# AS32x601 register map
File version: 1.0
CPU: RISC-V, little endian
Registers are 32-bit, read-write, reset 0x0 unless marked. A register's access mark holds for its fields unless they carry their own. Offsets are from the block's base; [hi:lo] are bit positions; {n}, {i} and the like mark numbered series.

## IWDG — Independent Watchdog Timer
Base 0x30104000
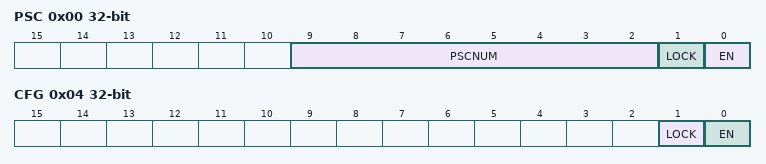
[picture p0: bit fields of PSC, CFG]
0x00 PSC — Prescaler register
  [9:2] PSCNUM — Independent watchdog prescaler number
  [1] LOCK — Independent watchdog prescaler lock
  [0] EN — Enable Independent watchdog prescaler
0x04 CFG — Configuration register
  [1] LOCK — Independent watchdog configuration lock
  [0] EN — Enable Independent watchdog configuration
0x08 DIV — Divider register
  [15:0] DIVNUM — Independent watchdog divider number
0x0C TO — Timeout period register
  [15:0] BVAL — Independent watchdog configure timeout period
0x10 CNT ro — Counter register
  [15:0] CNTNUM — Independent watchdog counter number
0x14 CLR wo — Clear/Refresh register
  [31:0] KEY — Independent watchdog refreshes the key

## WWDG0 — Window Watchdog 0
Base 0x5000D000
Same registers: WWDG1 0x5100C000
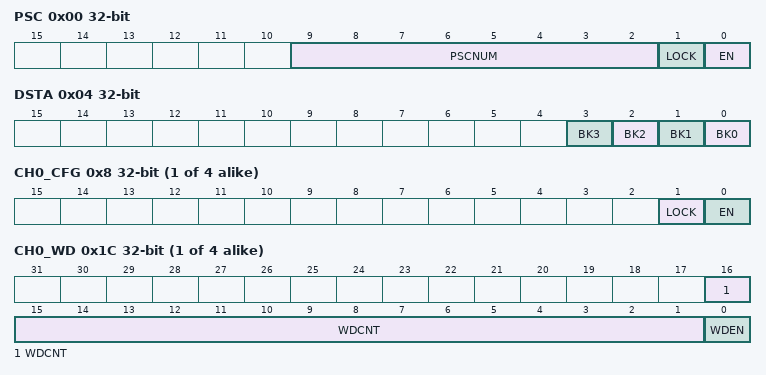
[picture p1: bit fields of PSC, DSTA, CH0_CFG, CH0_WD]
0x00 PSC — WWDG Prescaler register
  [9:2] PSCNUM — Independent watchdog prescaler number
  [1] LOCK — Independent watchdog prescaler lock
  [0] EN — Enable Independent watchdog prescaler
0x04 DSTA ro — WWDG Device Status register
  [n] BK{n} (n=0..3) — The WWDG Channel{n} Bark flag
{0x8+0x18*i} CH{i}_CFG (i=0..3) — WWDG Channel{i} Configuration register
  [1] LOCK — Independent watchdog configuration lock
  [0] EN — Enable Independent watchdog configuration
{0xC+0x18*i} CH{i}_DIV (i=0..3) — WWDG Channel{i} Divider register
  [15:0] DIVNUM — Independent watchdog divider number
{0x10+0x18*i} CH{i}_TO (i=0..3) — WWDG Channel{i} Timeout register
  [15:0] BVAL — Independent watchdog configure timeout period
{0x14+0x18*i} CH{i}_CNT (i=0..3) — WWDG Channel{i} Counter register
  [15:0] CNTNUM — Independent watchdog counter number
{0x18+0x18*i} CH{i}_CLR wo (i=0..3) — WWDG Channel{i} Clear register
  [31:0] KEY — Independent watchdog refreshes the key
{0x1C+0x18*i} CH{i}_WD (i=0..3) — WWDG Channel{i} Window register
  [16:1] WDCNT — WWDG Window Counter Value
  [0] WDEN — Enable WWDG Window Counter

## CRC — Cyclic Redundancy Check Calculation Unit
Base 0x5100D000
0x00 DR — CRC data register
  [31:0] DATA — CRC calculated result bit[31:0]
0x04 IDR — CRC independent data register
  [7:0] IDATA — Universal 8-bit data register bit[7:0]
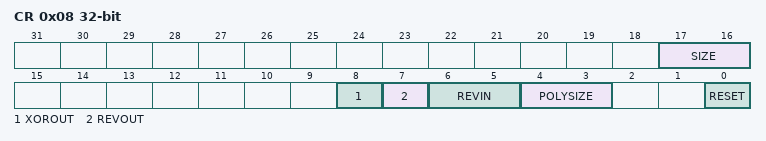
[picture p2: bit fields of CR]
0x08 CR — CRC control register
  [17:16] SIZE — Calculate the size of the data[1:0]
  [8] XOROUT — Output data XOR
  [7] REVOUT — Reverse output data
  [6:5] REVIN — Reverse input data[1:0]
  [4:3] POLYSIZE — Polynomial size[1:0]
  [0] RESET — Reset CRC
0x0C INIT reset 0xFFFFFFFF — CRC initial vector register
  [31:0] INIT — Initial vector register[31:0]
0x10 POLY wo — CRC generates polynomial registers
  [31:0] POLY — Generating polynomial register[31:0]
0x14 XOR wo — CRC XOR polynomial register
  [31:0] XOR — XOR register[31:0]

## CMU0 — Clock Monitoring Unit 0
Base 0x30003000
Same registers: CMU1 0x30003400, CMU2 0x30003800, CMU3 0x30003C00
0x00 CR — CMU Control register
  [2:0] MODE — MODE[2:0] bits (Clock monitoring enabled)
0x04 CCR — Counter configuration register
  [23:0] WINLEN — WINLEN[23:0] bits (Reference Count Window Length)
0x08 HTCR — High threshold configuration register
  [23:0] HFREF — HFREF[23:0] bits (High frequency reference threshold)
0x0C LTCR — Low threshold configuration register
  [23:0] LFREF — LFREF[23:0] bits (Low frequency reference threshold)
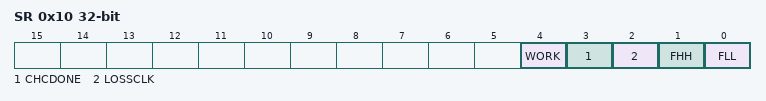
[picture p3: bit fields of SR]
0x10 SR ro — Status register
  [4] WORK — Working condition
  [3] CHCDONE — Status Detection
  [2] LOSSCLK — Clock loss status
  [1] FHH — State where the frequency is greater than the high-frequency reference threshold
  [0] FLL — Frequency below the low frequency reference threshold state

## GPIOH — General-purpose I/Os
Base 0x30102000
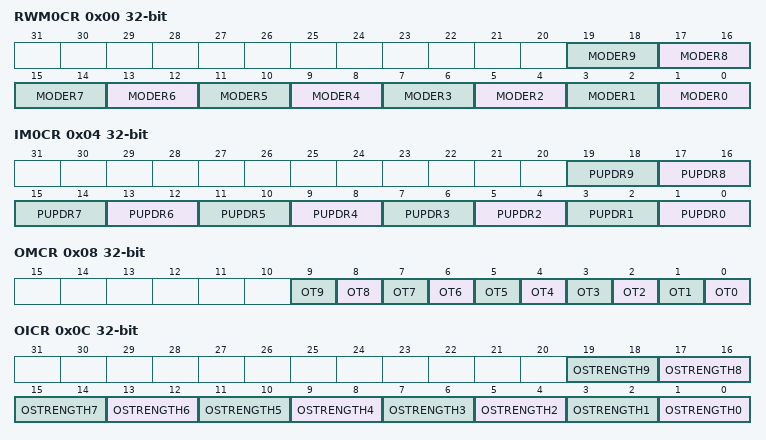
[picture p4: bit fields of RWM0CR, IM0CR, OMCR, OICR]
0x00 RWM0CR — Read/write mode control register 0
  [2n+1:2n] MODER{n} (n=0..9) — Control the read and write mode of Control {n}
0x04 IM0CR — Input mode control register 0
  [2n+1:2n] PUPDR{n} (n=0..9) — Channel {n} input mode control
0x08 OMCR — Output mode control register
  [n] OT{n} (n=0..9) — Channel {n} output mode control
0x0C OICR — Output intensity control register 0
  [2n+1:2n] OSTRENGTH{n} (n=0..9) — Channel {n} output strength control
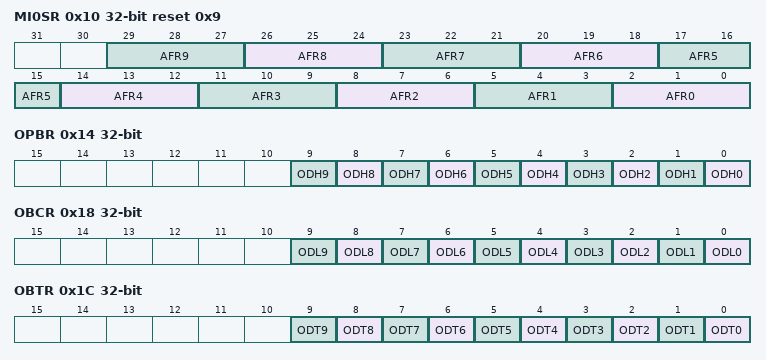
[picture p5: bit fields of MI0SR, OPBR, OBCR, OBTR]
0x10 MI0SR reset 0x9 — Multiplex interface select register 0
  [3n+2:3n] AFR{n} (n=0..9) — Channel {n} multiplexing interface selection
0x14 OPBR wo — Output position bit register
  [n] ODH{n} (n=0..9) — Channel {n} output set
0x18 OBCR wo — Output bit clear register
  [n] ODL{n} (n=0..9) — Channel {n} output clear
0x1C OBTR wo — Output bit flip register
  [n] ODT{n} (n=0..9) — Channel {n} output toggle
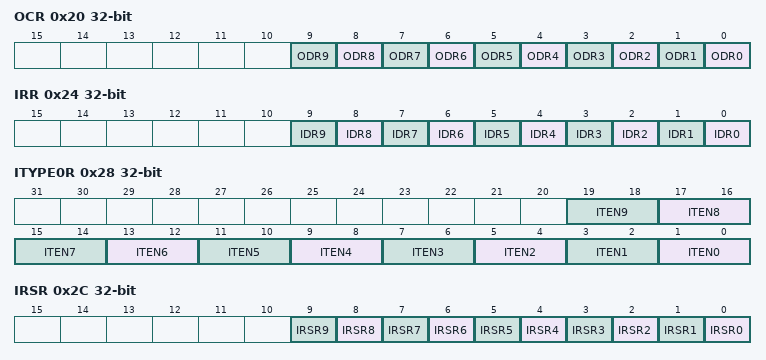
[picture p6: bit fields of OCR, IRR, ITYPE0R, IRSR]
0x20 OCR — Output control register
  [n] ODR{n} (n=0..9) — Channel {n} output control
0x24 IRR ro — Read interface register
  [n] IDR{n} (n=0..9) — Channel {n} input read
0x28 ITYPE0R — Interrupt type register 0
  [2n+1:2n] ITEN{n} (n=0..9) — Select the channel {n} interrupt type
0x2C IRSR — Interrupt Raw status Register
  [n] IRSR{n} (n=0..9) — Interrupt Raw status of channel {n}
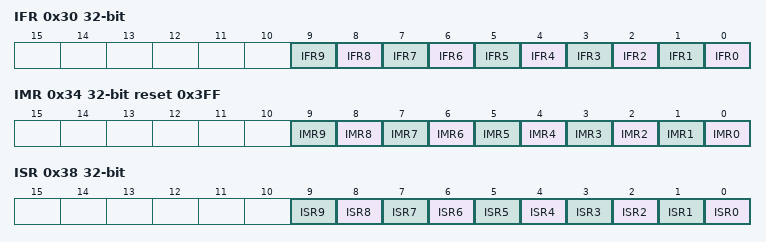
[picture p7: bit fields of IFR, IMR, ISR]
0x30 IFR — Interrupt Force Register
  [n] IFR{n} (n=0..9) — Channel {n} interrupt force
0x34 IMR reset 0x3FF — Interrupt Mask Register
  [n] IMR{n} (n=0..9) — Channel {n} interrupt mask
0x38 ISR ro — Interrupt status Register
  [n] ISR{n} (n=0..9) — Channel {n} interrupt status
